# TMS320F28069 register map
Vendor: Texas Instruments; Series: C2000 F2806x; File version: 0.2.0-generated
Registers are 16-bit, read-write, reset 0x0 unless marked. A register's access mark holds for its fields unless they carry their own. Offsets are from the block's base; [hi:lo] are bit positions; {n}, {i} and the like mark numbered series.

## VCU — VCU Registers
Base 0x00002400
{0x0+4i} VR{i} 32-bit (i=0..8) — General Purpose 32-bit registers
0x24 VT0 32-bit — Transition Bit register
0x28 VT1 32-bit — Transition Bit register
0x40 VSTATUS 32-bit — VCU Status Register
0x44 VCRC 32-bit — CRC Result register for un-secured memories

## CLA — CLA1 Registers
Base 0x00002800
0x00 MVECT1 — Task 1 vector
0x02 MVECT2 — Task 2 vector
0x04 MVECT3 — Task 3 vector
0x06 MVECT4 — Task 4 vector
0x08 MVECT5 — Task 5 vector
0x0A MVECT6 — Task 6 vector
0x0C MVECT7 — Task 7 vector
0x0E MVECT8 — Task 8 vector
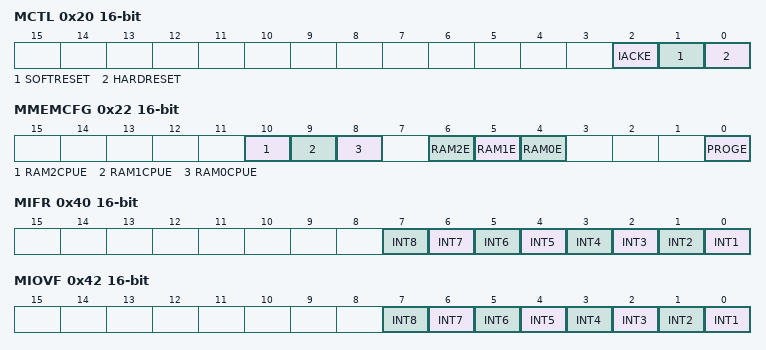
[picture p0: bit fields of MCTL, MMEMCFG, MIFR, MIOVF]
0x20 MCTL — CLA control
  [2] IACKE — IACK enable
  [1] SOFTRESET
  [0] HARDRESET
0x22 MMEMCFG — CLA memory configuration
  [10] RAM2CPUE — RAM2 CPU Access enable
  [9] RAM1CPUE — RAM1 CPU Access enable
  [8] RAM0CPUE — RAM0 CPU Access enable
  [6] RAM2E — RAM2 enable
  [5] RAM1E — RAM1 enable
  [4] RAM0E — RAM0 enable
  [0] PROGE — Program memory enable
0x28 MPISRCSEL1 32-bit — CLA interrupt source select
0x40 MIFR — CLA interrupt flag
  [n-1] INT{n} (n=1..8) — Interrupt {n} flag bit
0x42 MIOVF — CLA interrupt overflow flag
  [n-1] INT{n} (n=1..8) — Interrupt {n} overflow bit
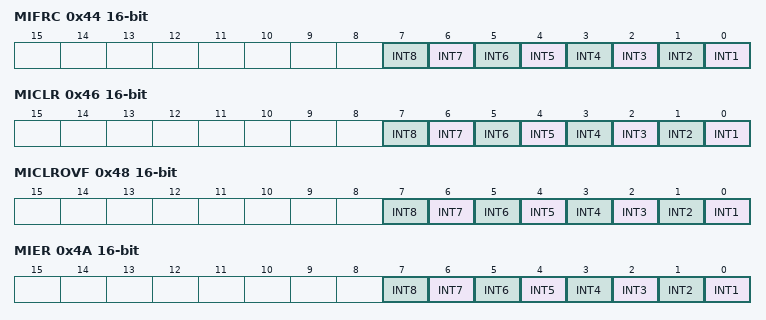
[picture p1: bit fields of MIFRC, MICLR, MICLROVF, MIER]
0x44 MIFRC — CLA interrupt force
  [n-1] INT{n} (n=1..8) — Interrupt {n} force bit
0x46 MICLR — CLA interrupt flag clear
  [n-1] INT{n} (n=1..8) — Interrupt {n} clear bit
0x48 MICLROVF — CLA interrupt overflow flag clear
  [n-1] INT{n} (n=1..8) — Interrupt {n} overflow clear bit
0x4A MIER — CLA interrupt enable
  [n-1] INT{n} (n=1..8) — Interrupt {n} enable bit
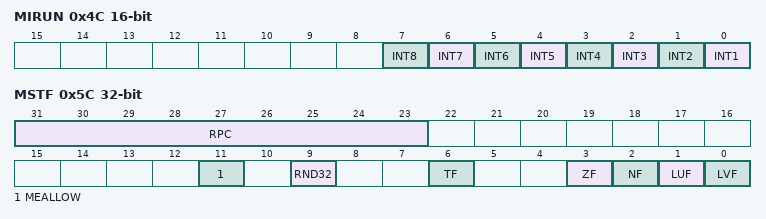
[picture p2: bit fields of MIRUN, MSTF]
0x4C MIRUN — CLA interrupt run status
  [n-1] INT{n} (n=1..8) — Interrupt {n} run status
0x50 MPC — CLA program counter
0x54 MAR0 — CLA auxillary register 0
0x56 MAR1 — CLA auxillary register 1
0x5C MSTF 32-bit — CLA floating-point status register
  [31:23] RPC — Return PC
  [11] MEALLOW — Protected write
  [9] RND32 — Rounding mode
  [6] TF — Test flag
  [3] ZF — Zero flag
  [2] NF — Negative flag
  [1] LUF — Underflow flag
  [0] LVF — Overflow flag
{0x60+8i} MR{i} 32-bit (i=0..3) — CLA result register {i}

## CLA0NOTVISIBLE
Base 0x00002800
0x2C MPISRCSEL2 32-bit — Peripheral Interrupt Source Select Register 2
0x4E MIPCTL — Interrupt Prioriry Register
0x80 MDEBUGCTL — Legacy CLA Debug Control Register
0x82 MDEBUGSS — Legacy CLA Debug Single Step Register
0x84 MPSACTL — CLA PSA Control Register
0x88 MPSA1 32-bit — CLA PSA Register 1
0x8C MPSA2 32-bit — CLA PSA Register 2
0xA0 MHWADBGCAP 32-bit — TI HWA Debug Capabilities
0xA4 MHWADBGCTL 32-bit — TI HWA Debug Control

## MCBSPA — Multi-Channel Buffered Serial Port Registers
Base 0x0000A000
0x00 DRR2 — McBSP Data Receive Register 2
0x02 DRR1 — McBSP Data Receive Register 1
0x04 DXR2 — McBSP Data Transmit Register 2
0x06 DXR1 — McBSP Data Transmit Register 1
0x08 SPCR2 — McBSP Serial Port Control Register 2
0x0A SPCR1 — McBSP Serial Port Control Register 1
0x0C RCR2 — McBSP Receive Control Register 2
0x0E RCR1 — McBSP Receive Control Register 1
0x10 XCR2 — McBSP Transmit Control Register 2
0x12 XCR1 — McBSP Transmit Control Register 1
0x14 SRGR2 — McBSP Sample Rate Generator Register 2
0x16 SRGR1 — McBSP Sample Rate Generator Register 1
0x18 MCR2 — McBSP Multichannel Register 2
0x1A MCR1 — McBSP Multichannel Register 1
0x1C RCERA — McBSP Receive Channel Enable Register Partition A
0x1E RCERB — McBSP Receive Channel Enable Register Partition B
0x20 XCERA — McBSP Transmit Channel Enable Register Partition A
0x22 XCERB — McBSP Transmit Channel Enable Register Partition B
0x24 PCR — McBSP Pin Control Register
0x26 RCERC — McBSP Receive Channel Enable Register Partition C
0x28 RCERD — McBSP Receive Channel Enable Register Partition D
0x2A XCERC — McBSP Transmit Channel Enable Register Partition C
0x2C XCERD — McBSP Transmit Channel Enable Register Partition D
0x2E RCERE — McBSP Receive Channel Enable Register Partition E
0x30 RCERF — McBSP Receive Channel Enable Register Partition F
0x32 XCERE — McBSP Transmit Channel Enable Register Partition E
0x34 XCERF — McBSP Transmit Channel Enable Register Partition F
0x36 RCERG — McBSP Receive Channel Enable Register Partition G
0x38 RCERH — McBSP Receive Channel Enable Register Partition H
0x3A XCERG — McBSP Transmit Channel Enable Register Partition G
0x3C XCERH — McBSP Transmit Channel Enable Register Partition H
0x46 MFFINT — McBSP Interrupt Enable Register
